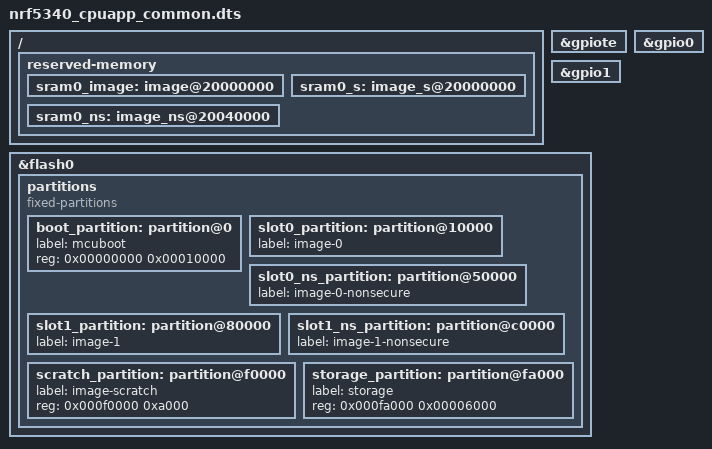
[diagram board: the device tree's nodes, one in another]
/*
 * Copyright (c) 2019-2020 Nordic Semiconductor ASA
 *
 * SPDX-License-Identifier: Apache-2.0
 */


&gpiote {
	status = "okay";
};

&gpio0 {
	status = "okay";
};

&gpio1 {
	status = "okay";
};

&flash0 {

	partitions {
		compatible = "fixed-partitions";
		#address-cells = <1>;
		#size-cells = <1>;

		boot_partition: partition@0 {
			label = "mcuboot";
			reg = <0x00000000 0x00010000>;
		};
		slot0_partition: partition@10000 {
			label = "image-0";
		};
		slot0_ns_partition: partition@50000 {
			label = "image-0-nonsecure";
		};
		slot1_partition: partition@80000 {
			label = "image-1";
		};
		slot1_ns_partition: partition@c0000 {
			label = "image-1-nonsecure";
		};
		scratch_partition: partition@f0000 {
			label = "image-scratch";
			reg = <0x000f0000 0xa000>;
		};
		storage_partition: partition@fa000 {
			label = "storage";
			reg = <0x000fa000 0x00006000>;
		};
	};
};

/ {

	reserved-memory {
		#address-cells = <1>;
		#size-cells = <1>;
		ranges;

		sram0_image: image@20000000 {
			/* Zephyr image(s) memory */
		};

		sram0_s: image_s@20000000 {
			/* Secure image memory */
		};

		sram0_ns: image_ns@20040000 {
			/* Non-Secure image memory */
		};
	};
};

/* Include partition configuration file */
#include "nrf5340_cpuapp_partition_conf.dts"
